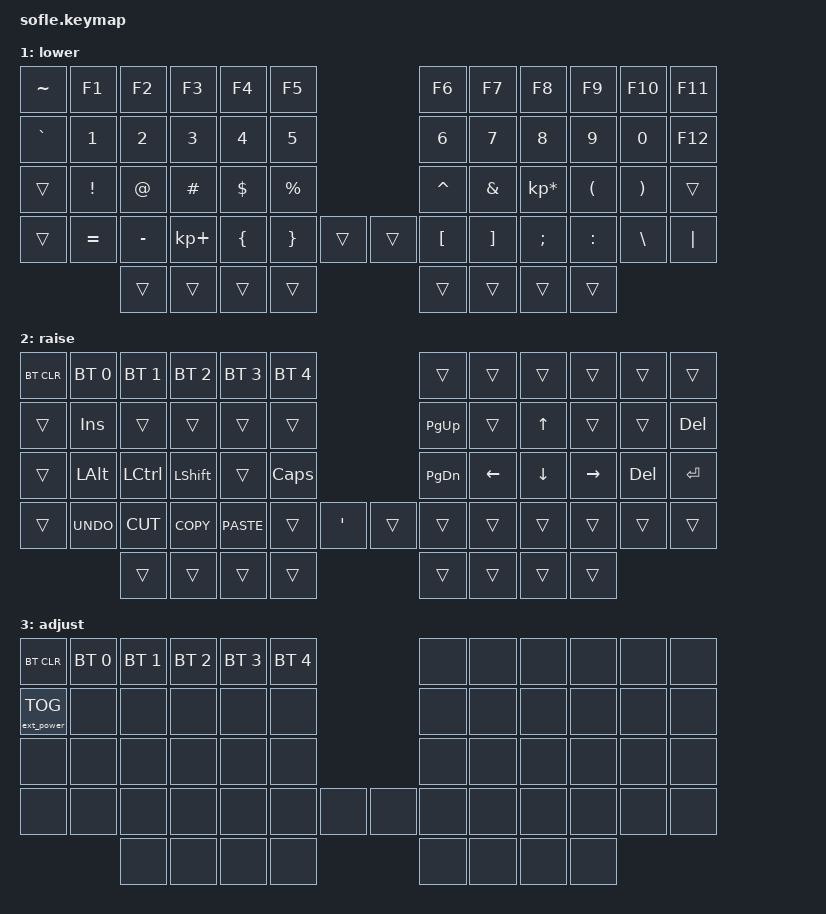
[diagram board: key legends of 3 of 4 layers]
/* 
 * Copyright (c) 2020 The ZMK Contributors
 *
 * SPDX-License-Identifier: MIT
 */

#include <behaviors.dtsi>
#include <dt-bindings/zmk/bt.h>
#include <dt-bindings/zmk/ext_power.h>
#include <dt-bindings/zmk/keys.h>
#include <dt-bindings/zmk/rgb.h>

#define BASE 0
#define LOWER 1
#define RAISE 2
#define ADJUST 3

/ {
    // Activate ADJUST layer by pressing raise and lower

    conditional_layers {
        compatible = "zmk,conditional-layers";

        adjust_layer {
            if-layers = <LOWER RAISE>;
            then-layer = <ADJUST>;
        };
    };

    keymap {
        compatible = "zmk,keymap";

        default_layer {
            label = "default";

            // TODO: At this time, the nav switch doesn't work.
            // Resolution notes: I have what I understand the nav switch code programmed in, for example, but as noted it does not function at this time.

            bindings = <
            // ┏━━━━━━━━━━━━━━━┳━━━━━━━━━━━━━━━┳━━━━━━━━━━━━━━━┳━━━━━━━━━━━━━━━┳━━━━━━━━━━━━━━━┳━━━━━━━━━━━━━━━┓                                  ┏━━━━━━━━━━━━━━━┳━━━━━━━━━━━━━━━┳━━━━━━━━━━━━━━━┳━━━━━━━━━━━━━━━┳━━━━━━━━━━━━━━━┳━━━━━━━━━━━━━━━┓
            // ┃      ESC      ┃       1       ┃       2       ┃       3       ┃       4       ┃       5       ┃                                  ┃       6       ┃       7       ┃       8       ┃       9       ┃       0       ┃       -       ┃
                    &kp ESC         &kp N1          &kp N2          &kp N3          &kp N4          &kp N5                                             &kp N6          &kp N7          &kp N8          &kp N9          &kp N0         &kp MINUS
            // ┣━━━━━━━━━━━━━━━╋━━━━━━━━━━━━━━━╋━━━━━━━━━━━━━━━╋━━━━━━━━━━━━━━━╋━━━━━━━━━━━━━━━╋━━━━━━━━━━━━━━━┫                                  ┣━━━━━━━━━━━━━━━╋━━━━━━━━━━━━━━━╋━━━━━━━━━━━━━━━╋━━━━━━━━━━━━━━━╋━━━━━━━━━━━━━━━╋━━━━━━━━━━━━━━━┫
            // ┃      TAB      ┃       Q       ┃       W       ┃       E       ┃       R       ┃       T       ┃                                  ┃       Y       ┃       U       ┃       I       ┃       O       ┃       P       ┃     BKSPC     ┃
                    &kp TAB          &kp Q           &kp W           &kp E           &kp R           &kp T                                              &kp Y           &kp U           &kp I           &kp O           &kp P         &kp BSPC
            // ┣━━━━━━━━━━━━━━━╋━━━━━━━━━━━━━━━╋━━━━━━━━━━━━━━━╋━━━━━━━━━━━━━━━╋━━━━━━━━━━━━━━━╋━━━━━━━━━━━━━━━┫                                  ┣━━━━━━━━━━━━━━━╋━━━━━━━━━━━━━━━╋━━━━━━━━━━━━━━━╋━━━━━━━━━━━━━━━╋━━━━━━━━━━━━━━━╋━━━━━━━━━━━━━━━┫
            // ┃      CAPS     ┃       A       ┃       S       ┃       D       ┃       F       ┃       G       ┃                                  ┃       H       ┃       J       ┃       K       ┃       L       ┃       ;       ┃       '       ┃
                    &kp CLCK         &kp A           &kp S           &kp D           &kp F           &kp G                                              &kp H           &kp J           &kp K           &kp L          &kp SEMI        &kp APOS    
            // ┣━━━━━━━━━━━━━━━╋━━━━━━━━━━━━━━━╋━━━━━━━━━━━━━━━╋━━━━━━━━━━━━━━━╋━━━━━━━━━━━━━━━╋━━━━━━━━━━━━━━━╋━━━━━━━━━━━━━━━┓  ┏━━━━━━━━━━━━━━━╋━━━━━━━━━━━━━━━╋━━━━━━━━━━━━━━━╋━━━━━━━━━━━━━━━╋━━━━━━━━━━━━━━━╋━━━━━━━━━━━━━━━╋━━━━━━━━━━━━━━━┫
            // ┃     SHIFT     ┃       Z       ┃       X       ┃       C       ┃       V       ┃       B       ┃     ENTER     ┃  ┃     SPACE     ┃       N       ┃       M       ┃       ,       ┃       .       ┃       /       ┃     SHIFT     ┃
                 &kp LEFT_SHIFT      &kp Z           &kp X           &kp C           &kp V           &kp B          &kp RET           &kp SPACE         &kp N           &kp M         &kp COMMA        &kp DOT         &kp FSLH    &kp RIGHT_SHIFT
            // ┗━━━━━━━━━━━━━━━┻━━━━━━━━━━━━━━━╋━━━━━━━━━━━━━━━╋━━━━━━━━━━━━━━━╋━━━━━━━━━━━━━━━╋━━━━━━━━━━━━━━━┫               ┃  ┃               ┣━━━━━━━━━━━━━━━╋━━━━━━━━━━━━━━━╋━━━━━━━━━━━━━━━╋━━━━━━━━━━━━━━━╋━━━━━━━━━━━━━━━┻━━━━━━━━━━━━━━━┛
            //                   encoder press ┃      GUI      ┃      ALT      ┃      CTRL     ┃     LOWER     ┃               ┃  ┃               ┃     RAISE     ┃     CTRL      ┃      ALT      ┃      GUI      ┃
                                   &kp C_MUTE      &kp LGUI        &kp LALT        &kp LCTRL       &mo LOWER                                          &mo RAISE       &kp RCTRL       &kp RALT        &kp RGUI
            //                                 ┗━━━━━━━━━━━━━━━┻━━━━━━━━━━━━━━━┻━━━━━━━━━━━━━━━┻━━━━━━━━━━━━━━━┻━━━━━━━━━━━━━━━┛  ┗━━━━━━━━━━━━━━━┻━━━━━━━━━━━━━━━┻━━━━━━━━━━━━━━━┻━━━━━━━━━━━━━━━┻━━━━━━━━━━━━━━━┛   
            //                                                                                                          5-Way Nav Switch
                                                                                                &kp A           &kp S           &kp D           &kp F           &kp G
            >;
            sensor-bindings = <&inc_dec_kp C_VOL_DN C_VOL_UP &inc_dec_kp PG_DN PG_UP>;
        };

        lower_layer {
            label = "lower";

            // TODO: 
            // Resolution notes:

            bindings = <
            // ┏━━━━━━━━━━━━━━━┳━━━━━━━━━━━━━━━┳━━━━━━━━━━━━━━━┳━━━━━━━━━━━━━━━┳━━━━━━━━━━━━━━━┳━━━━━━━━━━━━━━━┓                                  ┏━━━━━━━━━━━━━━━┳━━━━━━━━━━━━━━━┳━━━━━━━━━━━━━━━┳━━━━━━━━━━━━━━━┳━━━━━━━━━━━━━━━┳━━━━━━━━━━━━━━━┓
            // ┃        ~      ┃       F1      ┃       F2      ┃       F3      ┃       F4      ┃       F5      ┃                                  ┃       F6      ┃       F7      ┃       F8      ┃       F9      ┃       F10     ┃       F11     ┃
                  &kp TILDE          &kp F1          &kp F2          &kp F3          &kp F4          &kp F5                                             &kp F6          &kp F7          &kp F8          &kp F9          &kp F10         &kp F11
            // ┣━━━━━━━━━━━━━━━╋━━━━━━━━━━━━━━━╋━━━━━━━━━━━━━━━╋━━━━━━━━━━━━━━━╋━━━━━━━━━━━━━━━╋━━━━━━━━━━━━━━━┫                                  ┣━━━━━━━━━━━━━━━╋━━━━━━━━━━━━━━━╋━━━━━━━━━━━━━━━╋━━━━━━━━━━━━━━━╋━━━━━━━━━━━━━━━╋━━━━━━━━━━━━━━━┫
            // ┃        `      ┃       1       ┃       2       ┃       3       ┃       4       ┃       5       ┃                                  ┃       6       ┃       7       ┃       8       ┃       9       ┃       0       ┃       F12     ┃
                   &kp GRAVE         &kp N1          &kp N2          &kp N3          &kp N4          &kp N5                                             &kp N6          &kp N7          &kp N8          &kp N9          &kp N0          &kp F12
            // ┣━━━━━━━━━━━━━━━╋━━━━━━━━━━━━━━━╋━━━━━━━━━━━━━━━╋━━━━━━━━━━━━━━━╋━━━━━━━━━━━━━━━╋━━━━━━━━━━━━━━━┫                                  ┣━━━━━━━━━━━━━━━╋━━━━━━━━━━━━━━━╋━━━━━━━━━━━━━━━╋━━━━━━━━━━━━━━━╋━━━━━━━━━━━━━━━╋━━━━━━━━━━━━━━━┫
            // ┃               ┃       !       ┃       @       ┃       #       ┃       $       ┃       %       ┃                                  ┃       ^       ┃       &       ┃       *       ┃       (       ┃       )       ┃               ┃
                    &trans         &kp EXCL         &kp AT         &kp HASH       &kp DLLR        &kp PRCNT                                          &kp CARET        &kp AMPS    &kp KP_MULTIPLY     &kp LPAR        &kp RPAR          &trans
            // ┣━━━━━━━━━━━━━━━╋━━━━━━━━━━━━━━━╋━━━━━━━━━━━━━━━╋━━━━━━━━━━━━━━━╋━━━━━━━━━━━━━━━╋━━━━━━━━━━━━━━━╋━━━━━━━━━━━━━━━┓  ┏━━━━━━━━━━━━━━━╋━━━━━━━━━━━━━━━╋━━━━━━━━━━━━━━━╋━━━━━━━━━━━━━━━╋━━━━━━━━━━━━━━━╋━━━━━━━━━━━━━━━╋━━━━━━━━━━━━━━━┫
            // ┃               ┃       =       ┃       -       ┃       +       ┃       {       ┃       }       ┃               ┃  ┃               ┃       [       ┃       ]       ┃       ;       ┃       :       ┃       \       ┃       |       ┃
                    &trans         &kp EQUAL      &kp MINUS      &kp KP_PLUS       &kp LBRC        &kp RBRC         &trans             &trans         &kp LBKT        &kp RBKT        &kp SEMI       &kp COLON       &kp BSLH         &kp PIPE
            // ┗━━━━━━━━━━━━━━━┻━━━━━━━━━━━━━━━╋━━━━━━━━━━━━━━━╋━━━━━━━━━━━━━━━╋━━━━━━━━━━━━━━━╋━━━━━━━━━━━━━━━┫               ┃  ┃               ┣━━━━━━━━━━━━━━━╋━━━━━━━━━━━━━━━╋━━━━━━━━━━━━━━━╋━━━━━━━━━━━━━━━╋━━━━━━━━━━━━━━━┻━━━━━━━━━━━━━━━┛
            //                                 ┃               ┃               ┃               ┃               ┃               ┃  ┃               ┃               ┃               ┃               ┃               ┃
                                                    &trans           &trans          &trans          &trans                                            &trans          &trans          &trans          &trans
            //                                 ┗━━━━━━━━━━━━━━━┻━━━━━━━━━━━━━━━┻━━━━━━━━━━━━━━━┻━━━━━━━━━━━━━━━┻━━━━━━━━━━━━━━━┛  ┗━━━━━━━━━━━━━━━┻━━━━━━━━━━━━━━━┻━━━━━━━━━━━━━━━┻━━━━━━━━━━━━━━━┻━━━━━━━━━━━━━━━┛
            >;
            sensor-bindings = <&inc_dec_kp C_VOL_DN C_VOL_UP &inc_dec_kp PG_DN PG_UP>;
        };

        raise_layer {
            label = "raise";

            // TODO: 
            // Resolution notes:

            bindings = <
            // ┏━━━━━━━━━━━━━━━┳━━━━━━━━━━━━━━━┳━━━━━━━━━━━━━━━┳━━━━━━━━━━━━━━━┳━━━━━━━━━━━━━━━┳━━━━━━━━━━━━━━━┓                                  ┏━━━━━━━━━━━━━━━┳━━━━━━━━━━━━━━━┳━━━━━━━━━━━━━━━┳━━━━━━━━━━━━━━━┳━━━━━━━━━━━━━━━┳━━━━━━━━━━━━━━━┓
            // ┃     BTCLR     ┃      BT1      ┃      BT2      ┃      BT3      ┃      BT4      ┃      BT5      ┃                                  ┃               ┃               ┃               ┃               ┃               ┃               ┃
                  &bt BT_CLR     &bt BT_SEL 0     &bt BT_SEL 1    &bt BT_SEL 2    &bt BT_SEL 3    &bt BT_SEL 4                                          &trans          &trans          &trans          &trans          &trans         &trans
            // ┣━━━━━━━━━━━━━━━╋━━━━━━━━━━━━━━━╋━━━━━━━━━━━━━━━╋━━━━━━━━━━━━━━━╋━━━━━━━━━━━━━━━╋━━━━━━━━━━━━━━━┫                                  ┣━━━━━━━━━━━━━━━╋━━━━━━━━━━━━━━━╋━━━━━━━━━━━━━━━╋━━━━━━━━━━━━━━━╋━━━━━━━━━━━━━━━╋━━━━━━━━━━━━━━━┫
            // ┃               ┃      INS      ┃               ┃               ┃               ┃               ┃                                  ┃     PGUP      ┃               ┃       ^       ┃               ┃               ┃      DEL      ┃
                     &trans         &kp INS          &trans         &trans          &trans          &trans                                           &kp PG_UP         &trans          &kp UP          &trans          &trans         &kp DEL          
            // ┣━━━━━━━━━━━━━━━╋━━━━━━━━━━━━━━━╋━━━━━━━━━━━━━━━╋━━━━━━━━━━━━━━━╋━━━━━━━━━━━━━━━╋━━━━━━━━━━━━━━━┫                                  ┣━━━━━━━━━━━━━━━╋━━━━━━━━━━━━━━━╋━━━━━━━━━━━━━━━╋━━━━━━━━━━━━━━━╋━━━━━━━━━━━━━━━╋━━━━━━━━━━━━━━━┫
            // ┃               ┃      ALT      ┃      CTRL     ┃     SHIFT     ┃               ┃      CAPS     ┃                                  ┃     PGDN      ┃       <-      ┃       v       ┃      ->       ┃      DEL      ┃     ENTER     ┃
                     &trans       &kp LALT        &kp LCTRL       &kp LSHFT         &trans         &kp CLCK                                          &kp PG_DN        &kp LEFT        &kp DOWN       &kp RIGHT         &kp DEL         &kp RET
            // ┣━━━━━━━━━━━━━━━╋━━━━━━━━━━━━━━━╋━━━━━━━━━━━━━━━╋━━━━━━━━━━━━━━━╋━━━━━━━━━━━━━━━╋━━━━━━━━━━━━━━━╋━━━━━━━━━━━━━━━┓  ┏━━━━━━━━━━━━━━━╋━━━━━━━━━━━━━━━╋━━━━━━━━━━━━━━━╋━━━━━━━━━━━━━━━╋━━━━━━━━━━━━━━━╋━━━━━━━━━━━━━━━╋━━━━━━━━━━━━━━━┫
            // ┃               ┃      UNDO     ┃      CUT      ┃      COPY     ┃     PASTE     ┃               ┃       '       ┃  ┃               ┃               ┃               ┃               ┃               ┃               ┃               ┃
                     &trans        &kp K_UNDO      &kp K_CUT       &kp K_COPY     &kp K_PASTE        &trans        &kp APOS             &trans          &trans          &trans          &trans          &trans          &trans          &trans
            // ┗━━━━━━━━━━━━━━━┻━━━━━━━━━━━━━━━╋━━━━━━━━━━━━━━━╋━━━━━━━━━━━━━━━╋━━━━━━━━━━━━━━━╋━━━━━━━━━━━━━━━┫               ┃  ┃               ┣━━━━━━━━━━━━━━━╋━━━━━━━━━━━━━━━╋━━━━━━━━━━━━━━━╋━━━━━━━━━━━━━━━╋━━━━━━━━━━━━━━━┻━━━━━━━━━━━━━━━┛
            //                                 ┃               ┃               ┃               ┃               ┃               ┃  ┃               ┃               ┃               ┃               ┃               ┃
                                                     &trans          &trans          &trans          &trans                                             &trans          &trans          &trans          &trans
            //                                 ┗━━━━━━━━━━━━━━━┻━━━━━━━━━━━━━━━┻━━━━━━━━━━━━━━━┻━━━━━━━━━━━━━━━┻━━━━━━━━━━━━━━━┛  ┗━━━━━━━━━━━━━━━┻━━━━━━━━━━━━━━━┻━━━━━━━━━━━━━━━┻━━━━━━━━━━━━━━━┻━━━━━━━━━━━━━━━┛
            >;
            sensor-bindings = <&inc_dec_kp C_VOL_DN C_VOL_UP &inc_dec_kp PG_DN PG_UP>;
        };

        adjust_layer {
            label = "adjust";

            // TODO: 
            // Resolution notes:

            bindings = <
            // ┏━━━━━━━━━━━━━━━┳━━━━━━━━━━━━━━━┳━━━━━━━━━━━━━━━┳━━━━━━━━━━━━━━━┳━━━━━━━━━━━━━━━┳━━━━━━━━━━━━━━━┓                                  ┏━━━━━━━━━━━━━━━┳━━━━━━━━━━━━━━━┳━━━━━━━━━━━━━━━┳━━━━━━━━━━━━━━━┳━━━━━━━━━━━━━━━┳━━━━━━━━━━━━━━━┓
            // ┃     BTCLR     ┃      BT1      ┃      BT2      ┃      BT3      ┃      BT4      ┃      BT5      ┃                                  ┃               ┃               ┃               ┃               ┃               ┃               ┃
                  &bt BT_CLR     &bt BT_SEL 0     &bt BT_SEL 1    &bt BT_SEL 2    &bt BT_SEL 3    &bt BT_SEL 4                                          &none           &none           &none           &none           &none           &none  
            // ┣━━━━━━━━━━━━━━━╋━━━━━━━━━━━━━━━╋━━━━━━━━━━━━━━━╋━━━━━━━━━━━━━━━╋━━━━━━━━━━━━━━━╋━━━━━━━━━━━━━━━┫                                  ┣━━━━━━━━━━━━━━━╋━━━━━━━━━━━━━━━╋━━━━━━━━━━━━━━━╋━━━━━━━━━━━━━━━╋━━━━━━━━━━━━━━━╋━━━━━━━━━━━━━━━┫
            // ┃     EXTPWR    ┃               ┃               ┃               ┃               ┃               ┃                                  ┃               ┃               ┃               ┃               ┃               ┃               ┃
               &ext_power EP_TOG     &none           &none           &none           &none           &none                                              &none           &none           &none           &none           &none           &none
            // ┣━━━━━━━━━━━━━━━╋━━━━━━━━━━━━━━━╋━━━━━━━━━━━━━━━╋━━━━━━━━━━━━━━━╋━━━━━━━━━━━━━━━╋━━━━━━━━━━━━━━━┫                                  ┣━━━━━━━━━━━━━━━╋━━━━━━━━━━━━━━━╋━━━━━━━━━━━━━━━╋━━━━━━━━━━━━━━━╋━━━━━━━━━━━━━━━╋━━━━━━━━━━━━━━━┫
            // ┃               ┃               ┃               ┃               ┃               ┃               ┃                                  ┃               ┃               ┃               ┃               ┃               ┃               ┃
                     &none           &none           &none           &none           &none           &none                                              &none           &none           &none           &none           &none           &none
            // ┣━━━━━━━━━━━━━━━╋━━━━━━━━━━━━━━━╋━━━━━━━━━━━━━━━╋━━━━━━━━━━━━━━━╋━━━━━━━━━━━━━━━╋━━━━━━━━━━━━━━━╋━━━━━━━━━━━━━━━┓  ┏━━━━━━━━━━━━━━━╋━━━━━━━━━━━━━━━╋━━━━━━━━━━━━━━━╋━━━━━━━━━━━━━━━╋━━━━━━━━━━━━━━━╋━━━━━━━━━━━━━━━╋━━━━━━━━━━━━━━━┫
            // ┃               ┃               ┃               ┃               ┃               ┃               ┃               ┃  ┃               ┃               ┃               ┃               ┃               ┃               ┃               ┃
                     &none           &none           &none           &none           &none           &none           &none              &none           &none           &none           &none           &none           &none           &none
            // ┗━━━━━━━━━━━━━━━┻━━━━━━━━━━━━━━━╋━━━━━━━━━━━━━━━╋━━━━━━━━━━━━━━━╋━━━━━━━━━━━━━━━╋━━━━━━━━━━━━━━━┫               ┃  ┃               ┣━━━━━━━━━━━━━━━╋━━━━━━━━━━━━━━━╋━━━━━━━━━━━━━━━╋━━━━━━━━━━━━━━━╋━━━━━━━━━━━━━━━┻━━━━━━━━━━━━━━━┛
            //                                 ┃               ┃               ┃               ┃               ┃               ┃  ┃               ┃               ┃               ┃               ┃               ┃
                                                     &none           &none           &none           &none                                              &none           &none           &none           &none
            //                                 ┗━━━━━━━━━━━━━━━┻━━━━━━━━━━━━━━━┻━━━━━━━━━━━━━━━┻━━━━━━━━━━━━━━━┻━━━━━━━━━━━━━━━┛  ┗━━━━━━━━━━━━━━━┻━━━━━━━━━━━━━━━┻━━━━━━━━━━━━━━━┻━━━━━━━━━━━━━━━┻━━━━━━━━━━━━━━━┛
            >;
        };
    };
};

























            // empty layer for future development
            // ┏━━━━━━━━━━━━━━━┳━━━━━━━━━━━━━━━┳━━━━━━━━━━━━━━━┳━━━━━━━━━━━━━━━┳━━━━━━━━━━━━━━━┳━━━━━━━━━━━━━━━┓                                  ┏━━━━━━━━━━━━━━━┳━━━━━━━━━━━━━━━┳━━━━━━━━━━━━━━━┳━━━━━━━━━━━━━━━┳━━━━━━━━━━━━━━━┳━━━━━━━━━━━━━━━┓
            // ┃               ┃               ┃               ┃               ┃               ┃               ┃                                  ┃               ┃               ┃               ┃               ┃               ┃               ┃

            // ┣━━━━━━━━━━━━━━━╋━━━━━━━━━━━━━━━╋━━━━━━━━━━━━━━━╋━━━━━━━━━━━━━━━╋━━━━━━━━━━━━━━━╋━━━━━━━━━━━━━━━┫                                  ┣━━━━━━━━━━━━━━━╋━━━━━━━━━━━━━━━╋━━━━━━━━━━━━━━━╋━━━━━━━━━━━━━━━╋━━━━━━━━━━━━━━━╋━━━━━━━━━━━━━━━┫
            // ┃               ┃               ┃               ┃               ┃               ┃               ┃                                  ┃               ┃               ┃               ┃               ┃               ┃               ┃

            // ┣━━━━━━━━━━━━━━━╋━━━━━━━━━━━━━━━╋━━━━━━━━━━━━━━━╋━━━━━━━━━━━━━━━╋━━━━━━━━━━━━━━━╋━━━━━━━━━━━━━━━┫                                  ┣━━━━━━━━━━━━━━━╋━━━━━━━━━━━━━━━╋━━━━━━━━━━━━━━━╋━━━━━━━━━━━━━━━╋━━━━━━━━━━━━━━━╋━━━━━━━━━━━━━━━┫
            // ┃               ┃               ┃               ┃               ┃               ┃               ┃                                  ┃               ┃               ┃               ┃               ┃               ┃               ┃

            // ┣━━━━━━━━━━━━━━━╋━━━━━━━━━━━━━━━╋━━━━━━━━━━━━━━━╋━━━━━━━━━━━━━━━╋━━━━━━━━━━━━━━━╋━━━━━━━━━━━━━━━╋━━━━━━━━━━━━━━━┓  ┏━━━━━━━━━━━━━━━╋━━━━━━━━━━━━━━━╋━━━━━━━━━━━━━━━╋━━━━━━━━━━━━━━━╋━━━━━━━━━━━━━━━╋━━━━━━━━━━━━━━━╋━━━━━━━━━━━━━━━┫
            // ┃               ┃               ┃               ┃               ┃               ┃               ┃               ┃  ┃               ┃               ┃               ┃               ┃               ┃               ┃               ┃

            // ┗━━━━━━━━━━━━━━━┻━━━━━━━━━━━━━━━╋━━━━━━━━━━━━━━━╋━━━━━━━━━━━━━━━╋━━━━━━━━━━━━━━━╋━━━━━━━━━━━━━━━┫               ┃  ┃               ┣━━━━━━━━━━━━━━━╋━━━━━━━━━━━━━━━╋━━━━━━━━━━━━━━━╋━━━━━━━━━━━━━━━╋━━━━━━━━━━━━━━━┻━━━━━━━━━━━━━━━┛
            //                                 ┃               ┃               ┃               ┃               ┃               ┃  ┃               ┃               ┃               ┃               ┃               ┃

            //                                 ┗━━━━━━━━━━━━━━━┻━━━━━━━━━━━━━━━┻━━━━━━━━━━━━━━━┻━━━━━━━━━━━━━━━┻━━━━━━━━━━━━━━━┛  ┗━━━━━━━━━━━━━━━┻━━━━━━━━━━━━━━━┻━━━━━━━━━━━━━━━┻━━━━━━━━━━━━━━━┻━━━━━━━━━━━━━━━┛
